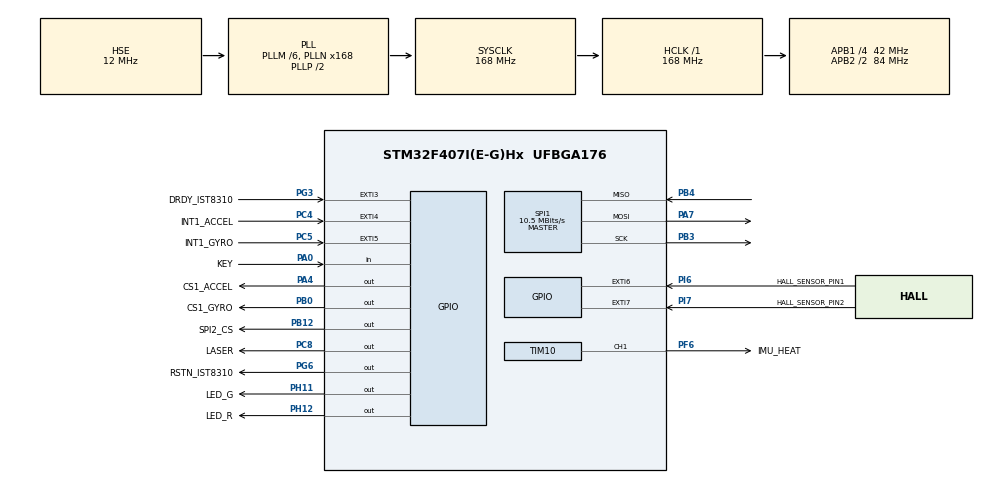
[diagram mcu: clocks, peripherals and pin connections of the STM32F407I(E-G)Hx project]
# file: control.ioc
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Dma.Request0=SPI1_RX
Dma.Request1=SPI1_TX
Dma.SPI1_RX.0.Direction=DMA_PERIPH_TO_MEMORY
Dma.SPI1_RX.0.FIFOMode=DMA_FIFOMODE_DISABLE
Dma.SPI1_RX.0.Instance=DMA2_Stream2
Dma.SPI1_RX.0.MemDataAlignment=DMA_MDATAALIGN_BYTE
Dma.SPI1_RX.0.MemInc=DMA_MINC_ENABLE
Dma.SPI1_RX.0.Mode=DMA_NORMAL
Dma.SPI1_RX.0.PeriphDataAlignment=DMA_PDATAALIGN_BYTE
Dma.SPI1_RX.0.PeriphInc=DMA_PINC_DISABLE
Dma.SPI1_RX.0.Priority=DMA_PRIORITY_VERY_HIGH
Dma.SPI1_TX.1.Direction=DMA_MEMORY_TO_PERIPH
Dma.SPI1_TX.1.FIFOMode=DMA_FIFOMODE_DISABLE
Dma.SPI1_TX.1.Instance=DMA2_Stream3
Dma.SPI1_TX.1.MemDataAlignment=DMA_MDATAALIGN_BYTE
Dma.SPI1_TX.1.MemInc=DMA_MINC_ENABLE
Dma.SPI1_TX.1.Mode=DMA_NORMAL
Dma.SPI1_TX.1.PeriphDataAlignment=DMA_PDATAALIGN_BYTE
Dma.SPI1_TX.1.PeriphInc=DMA_PINC_DISABLE
Dma.SPI1_TX.1.Priority=DMA_PRIORITY_HIGH
FREERTOS.Tasks01=INSTask,24,1024,StartINSTask,As weak,NULL,Dynamic,NULL,NULL;LED_RED,16,128,red_led_task,As weak,NULL,Dynamic,NULL,NULL;LED_GREEN,16,128,green_led_task,As weak,NULL,Dynamic,NULL,NULL
FREERTOS.configUSE_NEWLIB_REENTRANT=1
Mcu.Family=STM32F4
Mcu.Name=STM32F407I(E-G)Hx
Mcu.Package=UFBGA176
NVIC.DMA2_Stream2_IRQn=true\:5\:0\:true\:false\:false\:false\:false\:true\:true
NVIC.DMA2_Stream3_IRQn=true\:5\:0\:true\:false\:false\:false\:false\:true\:true
NVIC.EXTI3_IRQn=true\:5\:0\:true\:false\:true\:false\:true\:true\:true
NVIC.EXTI4_IRQn=true\:5\:0\:true\:false\:true\:false\:true\:true\:true
NVIC.EXTI9_5_IRQn=true\:5\:0\:true\:false\:true\:false\:true\:true\:true
NVIC.PriorityGroup=NVIC_PRIORITYGROUP_4
NVIC.TIM2_IRQn=true\:15\:0\:true\:false\:true\:false\:false\:true\:true
NVIC.TimeBase=TIM2_IRQn
NVIC.TimeBaseIP=TIM2
PA0-WKUP.GPIO_Label=KEY
PA0-WKUP.GPIO_PuPd=GPIO_PULLUP
PA0-WKUP.Signal=GPIO_Input
PA13.Mode=Serial_Wire
PA13.Signal=SYS_JTMS-SWDIO
PA14.Mode=Serial_Wire
PA14.Signal=SYS_JTCK-SWCLK
PA4.GPIO_Label=CS1_ACCEL
PA4.GPIO_PuPd=GPIO_PULLUP
PA4.GPIO_Speed=GPIO_SPEED_FREQ_HIGH
PA4.PinState=GPIO_PIN_SET
PA4.Signal=GPIO_Output
PA7.GPIO_PuPd=GPIO_PULLUP
PA7.Mode=Full_Duplex_Master
PA7.Signal=SPI1_MOSI
PA9.Signal=USART1_TX
PB0.GPIO_Label=CS1_GYRO
PB0.GPIO_PuPd=GPIO_PULLUP
PB0.GPIO_Speed=GPIO_SPEED_FREQ_HIGH
PB0.PinState=GPIO_PIN_SET
PB0.Signal=GPIO_Output
PB12.GPIO_Label=SPI2_CS
PB12.GPIO_PuPd=GPIO_PULLUP
PB12.GPIO_Speed=GPIO_SPEED_FREQ_MEDIUM
PB12.PinState=GPIO_PIN_SET
PB12.Signal=GPIO_Output
PB3.GPIO_PuPd=GPIO_PULLUP
PB3.Mode=Full_Duplex_Master
PB3.Signal=SPI1_SCK
PB4.GPIO_PuPd=GPIO_PULLUP
PB4.Mode=Full_Duplex_Master
PB4.Signal=SPI1_MISO
PB7.Signal=USART1_RX
PC4.GPIO_Label=INT1_ACCEL
PC4.GPIO_PuPd=GPIO_PULLUP
PC4.Signal=GPXTI4
PC5.GPIO_Label=INT1_GYRO
PC5.GPIO_PuPd=GPIO_PULLUP
PC5.Signal=GPXTI5
PC8.GPIO_Label=LASER
PC8.Signal=GPIO_Output
PD0.Signal=CAN1_RX
PD1.Signal=CAN1_TX
PF6.GPIO_Label=IMU_HEAT
PF6.GPIO_PuPd=GPIO_PULLUP
PF6.GPIO_Speed=GPIO_SPEED_FREQ_HIGH
PF6.Signal=S_TIM10_CH1
PG14.Signal=USART6_TX
PG3.GPIO_Label=DRDY_IST8310
PG3.GPIO_PuPd=GPIO_PULLUP
PG3.Signal=GPXTI3
PG6.GPIO_Label=RSTN_IST8310
PG6.GPIO_PuPd=GPIO_PULLUP
PG6.GPIO_Speed=GPIO_SPEED_FREQ_MEDIUM
PG6.PinState=GPIO_PIN_SET
PG6.Signal=GPIO_Output
PG9.Signal=USART6_RX
PH0-OSC_IN.Mode=HSE-External-Oscillator
PH0-OSC_IN.Signal=RCC_OSC_IN
PH1-OSC_OUT.Mode=HSE-External-Oscillator
PH1-OSC_OUT.Signal=RCC_OSC_OUT
PH11.GPIO_Label=LED_G
PH11.GPIO_PuPd=GPIO_PULLUP
PH11.GPIO_Speed=GPIO_SPEED_FREQ_MEDIUM
PH11.PinState=GPIO_PIN_SET
PH11.Signal=GPIO_Output
PH12.GPIO_Label=LED_R
PH12.GPIO_PuPd=GPIO_PULLUP
PH12.GPIO_Speed=GPIO_SPEED_FREQ_MEDIUM
PH12.PinState=GPIO_PIN_SET
PH12.Signal=GPIO_Output
PI6.GPIO_Label=HALL_SENSOR_PIN1
PI6.Signal=GPXTI6
PI7.GPIO_Label=HALL_SENSOR_PIN2
PI7.Signal=GPXTI7
ProjectManager.HeapSize=0x200
ProjectManager.StackSize=0x400
ProjectManager.TargetToolchain=STM32CubeIDE
RCC.48MHZClocksFreq_Value=84000000
RCC.AHBFreq_Value=168000000
RCC.APB1CLKDivider=RCC_HCLK_DIV4
RCC.APB1Freq_Value=42000000
RCC.APB1TimFreq_Value=84000000
RCC.APB2CLKDivider=RCC_HCLK_DIV2
RCC.APB2Freq_Value=84000000
RCC.APB2TimFreq_Value=168000000
RCC.CortexFreq_Value=168000000
RCC.HCLKFreq_Value=168000000
RCC.HSE_VALUE=12000000
RCC.HSI_VALUE=16000000
RCC.LSE_VALUE=32768
RCC.PLLM=6
RCC.PLLN=168
RCC.PLLSourceVirtual=RCC_PLLSOURCE_HSE
RCC.SYSCLKFreq_VALUE=168000000
RCC.SYSCLKSource=RCC_SYSCLKSOURCE_PLLCLK
RCC.VCOOutputFreq_Value=336000000
SH.S_TIM10_CH1.0=TIM10_CH1,PWM Generation1 CH1
SPI1.BaudRatePrescaler=SPI_BAUDRATEPRESCALER_8
SPI1.CLKPhase=SPI_PHASE_2EDGE
SPI1.CLKPolarity=SPI_POLARITY_HIGH
SPI1.CalculateBaudRate=10.5 MBits/s
SPI1.Direction=SPI_DIRECTION_2LINES
SPI1.Mode=SPI_MODE_MASTER
SPI1.VirtualType=VM_MASTER
TIM10.Channel=TIM_CHANNEL_1
TIM10.Period=2000-1
TIM10.Prescaler=84-1
VP_FREERTOS_VS_CMSIS_V2.Mode=CMSIS_V2
VP_SYS_VS_tim2.Mode=TIM2
VP_TIM10_VS_ClockSourceINT.Mode=Enable_Timer
board=custom

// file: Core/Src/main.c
/* USER CODE BEGIN Header */
/**
  ******************************************************************************
  * @file           : main.c
  * @brief          : Main program body
  ******************************************************************************
  * @attention
  *
  * Copyright (c) 2024 STMicroelectronics.
  * All rights reserved.
  *
  * This software is licensed under terms that can be found in the LICENSE file
  * in the root directory of this software component.
  * If no LICENSE file comes with this software, it is provided AS-IS.
  *
  ******************************************************************************
  */
/* USER CODE END Header */
#include "main.h"
#include "cmsis_os.h"
#include "dma.h"
#include "spi.h"
#include "tim.h"
#include "gpio.h"

/* USER CODE BEGIN Includes */
#include "BMI088driver.h"
#include "bsp_dwt.h"
#include "ins_task.h"
#include "led.h"
/* USER CODE END Includes */

/* USER CODE BEGIN PM */
// pid_type_def speed;
// float set_speed=0;
// int16_t delta;
// float speedmeasure;
// float set_speed_temp;
// int16_t max_speed_change = 50;
/* USER CODE END PM */

void SystemClock_Config(void);
void MX_FREERTOS_Init(void);

/* USER CODE BEGIN 0 */
// extern INS_t INS;
/* USER CODE END 0 */

int main(void)
{

  /* MCU Configuration--------------------------------------------------------*/

  /* Reset of all peripherals, Initializes the Flash interface and the Systick. */
  HAL_Init();

  /* Configure the system clock */
  SystemClock_Config();

  /* Initialize all configured peripherals */
  MX_GPIO_Init();
  MX_DMA_Init();
  MX_SPI1_Init();
  MX_TIM10_Init();
  /* USER CODE BEGIN 2 */
  DWT_Init(168);
  while (BMI088_init(&hspi1, 1) != BMI088_NO_ERROR)
    ;
  // INS_Init();

  /* USER CODE END 2 */

  /* Init scheduler */
  osKernelInitialize();  /* Call init function for freertos objects (in freertos.c) */
  MX_FREERTOS_Init();

  /* Start scheduler */
  osKernelStart();

  /* We should never get here as control is now taken by the scheduler */
  /* Infinite loop */
  while (1)
  {

  }
}

void SystemClock_Config(void)
{
  RCC_OscInitTypeDef RCC_OscInitStruct = {0};
  RCC_ClkInitTypeDef RCC_ClkInitStruct = {0};

  /** Configure the main internal regulator output voltage
  */
  __HAL_RCC_PWR_CLK_ENABLE();
  __HAL_PWR_VOLTAGESCALING_CONFIG(PWR_REGULATOR_VOLTAGE_SCALE1);

  /** Initializes the RCC Oscillators according to the specified parameters
  * in the RCC_OscInitTypeDef structure.
  */
  RCC_OscInitStruct.OscillatorType = RCC_OSCILLATORTYPE_HSE;
  RCC_OscInitStruct.HSEState = RCC_HSE_ON;
  RCC_OscInitStruct.PLL.PLLState = RCC_PLL_ON;
  RCC_OscInitStruct.PLL.PLLSource = RCC_PLLSOURCE_HSE;
  RCC_OscInitStruct.PLL.PLLM = 6;
  RCC_OscInitStruct.PLL.PLLN = 168;
  RCC_OscInitStruct.PLL.PLLP = RCC_PLLP_DIV2;
  RCC_OscInitStruct.PLL.PLLQ = 4;
  if (HAL_RCC_OscConfig(&RCC_OscInitStruct) != HAL_OK)
  {
    Error_Handler();
  }

  /** Initializes the CPU, AHB and APB buses clocks
  */
  RCC_ClkInitStruct.ClockType = RCC_CLOCKTYPE_HCLK|RCC_CLOCKTYPE_SYSCLK
                              |RCC_CLOCKTYPE_PCLK1|RCC_CLOCKTYPE_PCLK2;
  RCC_ClkInitStruct.SYSCLKSource = RCC_SYSCLKSOURCE_PLLCLK;
  RCC_ClkInitStruct.AHBCLKDivider = RCC_SYSCLK_DIV1;
  RCC_ClkInitStruct.APB1CLKDivider = RCC_HCLK_DIV4;
  RCC_ClkInitStruct.APB2CLKDivider = RCC_HCLK_DIV2;

  if (HAL_RCC_ClockConfig(&RCC_ClkInitStruct, FLASH_LATENCY_5) != HAL_OK)
  {
    Error_Handler();
  }
}

void HAL_TIM_PeriodElapsedCallback(TIM_HandleTypeDef *htim)
{
  if (htim->Instance == TIM2) {
    HAL_IncTick();
  }
}

void Error_Handler(void)
{
  __disable_irq();
  while (1)
  {
  }
}

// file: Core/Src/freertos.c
/* USER CODE BEGIN Header */
/**
  ******************************************************************************
  * File Name          : freertos.c
  * Description        : Code for freertos applications
  ******************************************************************************
  * @attention
  *
  * Copyright (c) 2024 STMicroelectronics.
  * All rights reserved.
  *
  * This software is licensed under terms that can be found in the LICENSE file
  * in the root directory of this software component.
  * If no LICENSE file comes with this software, it is provided AS-IS.
  *
  ******************************************************************************
  */
/* USER CODE END Header */

#include "FreeRTOS.h"
#include "task.h"
#include "main.h"
#include "cmsis_os.h"

/* Definitions for INSTask */
osThreadId_t INSTaskHandle;
const osThreadAttr_t INSTask_attributes = {
  .name = "INSTask",
  .stack_size = 1024 * 4,
  .priority = (osPriority_t) osPriorityNormal,
};
/* Definitions for LED_RED */
osThreadId_t LED_REDHandle;
const osThreadAttr_t LED_RED_attributes = {
  .name = "LED_RED",
  .stack_size = 128 * 4,
  .priority = (osPriority_t) osPriorityBelowNormal,
};
/* Definitions for LED_GREEN */
osThreadId_t LED_GREENHandle;
const osThreadAttr_t LED_GREEN_attributes = {
  .name = "LED_GREEN",
  .stack_size = 128 * 4,
  .priority = (osPriority_t) osPriorityBelowNormal,
};

void StartINSTask(void *argument);
void red_led_task(void *argument);
void green_led_task(void *argument);

void MX_FREERTOS_Init(void); /* (MISRA C 2004 rule 8.1) */

void MX_FREERTOS_Init(void) {

  /* Create the thread(s) */
  /* creation of INSTask */
  INSTaskHandle = osThreadNew(StartINSTask, NULL, &INSTask_attributes);

  /* creation of LED_RED */
  LED_REDHandle = osThreadNew(red_led_task, NULL, &LED_RED_attributes);

  /* creation of LED_GREEN */
  LED_GREENHandle = osThreadNew(green_led_task, NULL, &LED_GREEN_attributes);

}

__weak void StartINSTask(void *argument)
{
  for(;;)
  {
    osDelay(1);
  }
}

__weak void red_led_task(void *argument)
{
  for(;;)
  {
    osDelay(1);
  }
}

__weak void green_led_task(void *argument)
{
  for(;;)
  {
    osDelay(1);
  }
}
